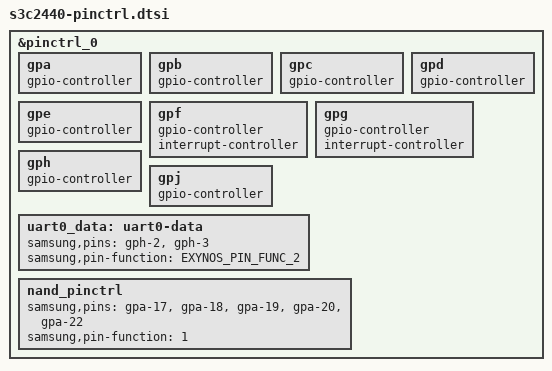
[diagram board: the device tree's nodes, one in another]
/*
 * Samsung S3C2416 pinctrl settings
 *
 * Copyright (c) 2013 Heiko Stuebner <heiko@sntech.de>
 *
 * This program is free software; you can redistribute it and/or modify
 * it under the terms of the GNU General Public License version 2 as
 * published by the Free Software Foundation.
 */

#include <dt-bindings/pinctrl/samsung.h>

&pinctrl_0 {
	/*
	 * Pin banks
	 */
    /*s3c2440只有GPA~GPJ*/
	gpa: gpa {
		gpio-controller;
		#gpio-cells = <2>;
	};

	gpb: gpb {
		gpio-controller;
		#gpio-cells = <2>;
	};

	gpc: gpc {
		gpio-controller;
		#gpio-cells = <2>;
	};

	gpd: gpd {
		gpio-controller;
		#gpio-cells = <2>;
	};

	gpe: gpe {
		gpio-controller;
		#gpio-cells = <2>;
	};

	gpf: gpf {
		gpio-controller;
		#gpio-cells = <2>;
		interrupt-controller;
		#interrupt-cells = <2>;
	};

	gpg: gpg {
		gpio-controller;
		#gpio-cells = <2>;
		interrupt-controller;
		#interrupt-cells = <2>;
	};

	gph: gph {
		gpio-controller;
		#gpio-cells = <2>;
	};

	gpj: gpj {
		gpio-controller;
		#gpio-cells = <2>;
	};

	/*
	 * Pin groups
	 */
	uart0_data: uart0-data {
		samsung,pins = "gph-2", "gph-3";
		samsung,pin-function = <EXYNOS_PIN_FUNC_2>;
	};
	/*添加NAND flash所用的管脚*/
	nand_pinctrl: nand_pinctrl {
	    samsung,pins = "gpa-17", "gpa-18", "gpa-19",
				     "gpa-20", "gpa-22";
	    samsung,pin-function = <1>;
    };

};

